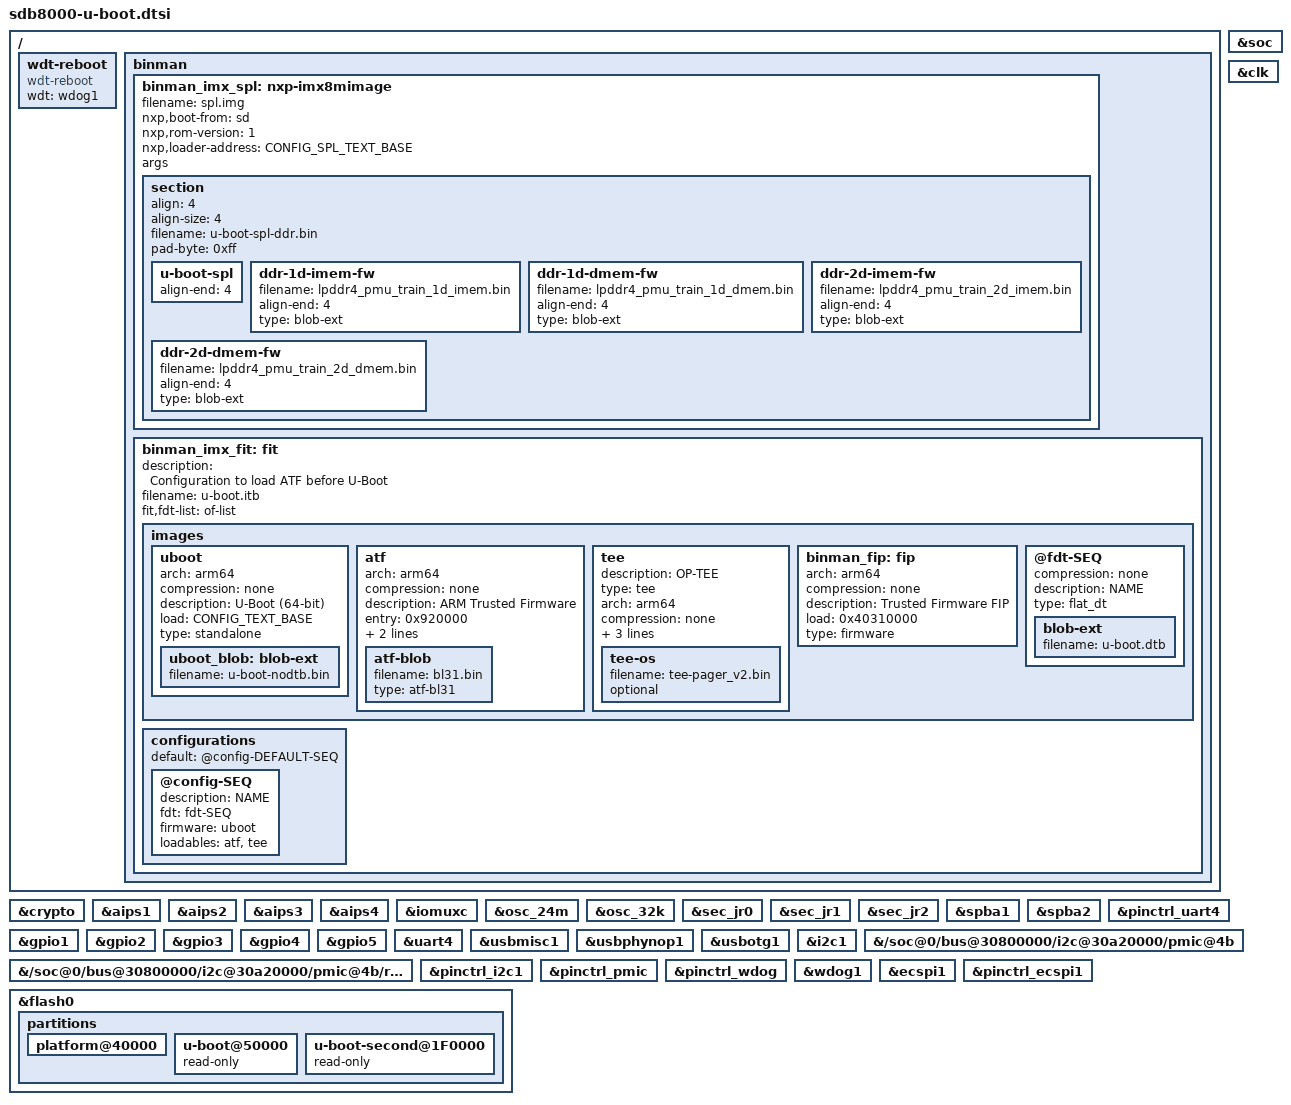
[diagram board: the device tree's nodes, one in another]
// SPDX-License-Identifier: GPL-2.0+
/*
 * Copyright 2026 Akkodis Edge Sweden AB
 */


/ {
	wdt-reboot {
		compatible = "wdt-reboot";
		wdt = <&wdog1>;
		bootph-pre-ram;
	};

	binman {
		binman_imx_spl: nxp-imx8mimage {
			filename = "spl.img";
			nxp,boot-from = "sd";
			nxp,rom-version = <1>;
			nxp,loader-address = <CONFIG_SPL_TEXT_BASE>;
			args;	/* Needed by mkimage etype superclass */

			section {
				align = <4>;
				align-size = <4>;
				filename = "u-boot-spl-ddr.bin";
				pad-byte = <0xff>;

				u-boot-spl {
					align-end = <4>;
				};

				ddr-1d-imem-fw {
					filename = "lpddr4_pmu_train_1d_imem.bin";
					align-end = <4>;
					type = "blob-ext";
				};

				ddr-1d-dmem-fw {
					filename = "lpddr4_pmu_train_1d_dmem.bin";
					align-end = <4>;
					type = "blob-ext";
				};

				ddr-2d-imem-fw {
					filename = "lpddr4_pmu_train_2d_imem.bin";
					align-end = <4>;
					type = "blob-ext";
				};

				ddr-2d-dmem-fw {
					filename = "lpddr4_pmu_train_2d_dmem.bin";
					align-end = <4>;
					type = "blob-ext";
				};
			};
		};

		binman_imx_fit: fit {
			description = "Configuration to load ATF before U-Boot";
			filename = "u-boot.itb";
			fit,fdt-list = "of-list";
			#address-cells = <1>;

			images {
				uboot {
					arch = "arm64";
					compression = "none";
					description = "U-Boot (64-bit)";
					load = <CONFIG_TEXT_BASE>;
					type = "standalone";

					uboot_blob: blob-ext {
						filename = "u-boot-nodtb.bin";
					};
				};

				atf {
					arch = "arm64";
					compression = "none";
					description = "ARM Trusted Firmware";
					entry = <0x920000>;
					load = <0x920000>;
					type = "firmware";

					atf-blob {
						filename = "bl31.bin";
						type = "atf-bl31";
					};
				};

				tee: tee {
					description = "OP-TEE";
					type = "tee";
					arch = "arm64";
					compression = "none";
					os = "tee";
					load = <CONFIG_IMX8M_OPTEE_LOAD_ADDR>;
					entry = <CONFIG_IMX8M_OPTEE_LOAD_ADDR>;

					tee-os {
						filename = "tee-pager_v2.bin";
						optional;
					};
				};

				binman_fip: fip {
					arch = "arm64";
					compression = "none";
					description = "Trusted Firmware FIP";
					load = <0x40310000>;
					type = "firmware";
				};

				@fdt-SEQ {
					compression = "none";
					description = "NAME";
					type = "flat_dt";

					blob-ext {
						filename = "u-boot.dtb";
					};
				};
			};

			configurations {
				default = "@config-DEFAULT-SEQ";

				@config-SEQ {
					description = "NAME";
					fdt = "fdt-SEQ";
					firmware = "uboot";
					loadables = "atf", "tee";
				};
			};
		};
	};
};

&soc {
	bootph-all;
	bootph-pre-ram;
};

&crypto {
	bootph-pre-ram;
};

&aips1 {
	bootph-all;
	bootph-pre-ram;
};

&aips2 {
	bootph-pre-ram;
};

&aips3 {
	bootph-pre-ram;
};

&aips4 {
	bootph-pre-ram;
};

&clk {
	bootph-all;
	bootph-pre-ram;
	/delete-property/ assigned-clocks;
	/delete-property/ assigned-clock-parents;
	/delete-property/ assigned-clock-rates;
};

&iomuxc {
	bootph-pre-ram;
};

&osc_24m {
	bootph-all;
	bootph-pre-ram;
};

&osc_32k {
	bootph-all;
	bootph-pre-ram;
};

&sec_jr0 {
	bootph-pre-ram;
};

&sec_jr1 {
	bootph-pre-ram;
};

&sec_jr2 {
	bootph-pre-ram;
};

&spba1 {
	bootph-all;
	bootph-pre-ram;
};

&spba2 {
	bootph-all;
	bootph-pre-ram;
};

&pinctrl_uart4 {
	bootph-pre-ram;
};

&gpio1 {
	bootph-pre-ram;
};

&gpio2 {
	bootph-pre-ram;
};

&gpio3 {
	bootph-pre-ram;
};

&gpio4 {
	bootph-pre-ram;
};

&gpio5 {
	bootph-pre-ram;
};

&uart4 {
	bootph-pre-ram;
};

&usbmisc1 {
	bootph-pre-ram;
};

&usbphynop1 {
	bootph-pre-ram;
};

&usbotg1 {
	bootph-pre-ram;
};

&i2c1 {
	bootph-pre-ram;
};

&{/soc@0/bus@30800000/i2c@30a20000/pmic@4b} {
	bootph-pre-ram;
};

&{/soc@0/bus@30800000/i2c@30a20000/pmic@4b/regulators} {
	bootph-pre-ram;
};

&pinctrl_i2c1 {
	bootph-pre-ram;
};

&pinctrl_pmic {
	bootph-pre-ram;
};

&pinctrl_wdog {
	bootph-pre-ram;
};

&wdog1 {
	bootph-pre-ram;
};

&ecspi1  {
	bootph-pre-ram;
};

&pinctrl_ecspi1 {
	bootph-pre-ram;
};

&flash0 {
	bootph-pre-ram;
	partitions {
		bootph-pre-ram;
		platform@40000 {
			bootph-pre-ram;
		};
		u-boot@50000 {
			bootph-pre-ram;
			read-only;
		};
		u-boot-second@1F0000 {
			bootph-pre-ram;
			read-only;
		};
	};
};
